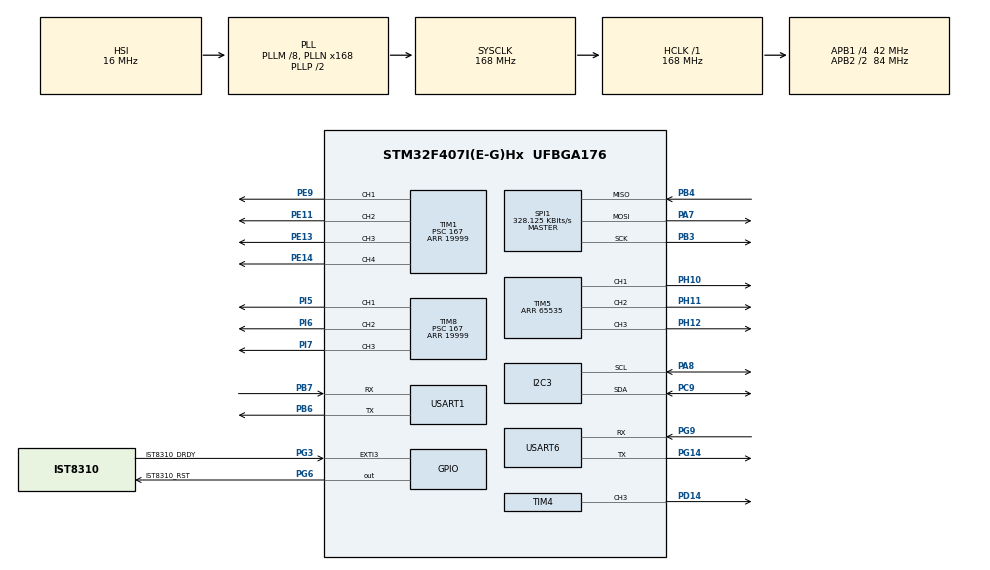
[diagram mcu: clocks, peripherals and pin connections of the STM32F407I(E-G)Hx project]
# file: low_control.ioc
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Dma.Request0=SPI1_RX
Dma.Request1=SPI1_TX
Dma.SPI1_RX.0.Direction=DMA_PERIPH_TO_MEMORY
Dma.SPI1_RX.0.FIFOMode=DMA_FIFOMODE_DISABLE
Dma.SPI1_RX.0.Instance=DMA2_Stream0
Dma.SPI1_RX.0.MemDataAlignment=DMA_MDATAALIGN_BYTE
Dma.SPI1_RX.0.MemInc=DMA_MINC_ENABLE
Dma.SPI1_RX.0.Mode=DMA_NORMAL
Dma.SPI1_RX.0.PeriphDataAlignment=DMA_PDATAALIGN_BYTE
Dma.SPI1_RX.0.PeriphInc=DMA_PINC_DISABLE
Dma.SPI1_RX.0.Priority=DMA_PRIORITY_VERY_HIGH
Dma.SPI1_TX.1.Direction=DMA_MEMORY_TO_PERIPH
Dma.SPI1_TX.1.FIFOMode=DMA_FIFOMODE_DISABLE
Dma.SPI1_TX.1.Instance=DMA2_Stream3
Dma.SPI1_TX.1.MemDataAlignment=DMA_MDATAALIGN_BYTE
Dma.SPI1_TX.1.MemInc=DMA_MINC_ENABLE
Dma.SPI1_TX.1.Mode=DMA_NORMAL
Dma.SPI1_TX.1.PeriphDataAlignment=DMA_PDATAALIGN_BYTE
Dma.SPI1_TX.1.PeriphInc=DMA_PINC_DISABLE
Dma.SPI1_TX.1.Priority=DMA_PRIORITY_HIGH
I2C3.I2C_Mode=I2C_Fast
Mcu.Family=STM32F4
Mcu.Name=STM32F407I(E-G)Hx
Mcu.Package=UFBGA176
NVIC.DMA2_Stream0_IRQn=true\:0\:0\:false\:false\:true\:false\:true\:true
NVIC.DMA2_Stream3_IRQn=true\:0\:0\:false\:false\:true\:false\:true\:true
NVIC.PriorityGroup=NVIC_PRIORITYGROUP_4
NVIC.USART1_IRQn=true\:0\:0\:false\:false\:true\:true\:true\:true
NVIC.USART6_IRQn=true\:0\:0\:false\:false\:true\:true\:true\:true
PA13.Mode=Serial_Wire
PA13.Signal=SYS_JTMS-SWDIO
PA14.Mode=Serial_Wire
PA14.Signal=SYS_JTCK-SWCLK
PA8.Mode=I2C
PA8.Signal=I2C3_SCL
PB3.Mode=Full_Duplex_Master
PB3.Signal=SPI1_SCK
PB4.Mode=Full_Duplex_Master
PB4.Signal=SPI1_MISO
PA7.Mode=Full_Duplex_Master
PA7.Signal=SPI1_MOSI
PB6.Mode=Asynchronous
PB6.Signal=USART1_TX
PB7.Mode=Asynchronous
PB7.Signal=USART1_RX
PD14.Signal=S_TIM4_CH3
PC9.Mode=I2C
PC9.Signal=I2C3_SDA
PE11.Signal=S_TIM1_CH2
PE13.Signal=S_TIM1_CH3
PE14.Signal=S_TIM1_CH4
PE9.Signal=S_TIM1_CH1
PG14.Mode=Asynchronous
PG14.Signal=USART6_TX
PG3.GPIO_Label=IST8310_DRDY
PG3.GPIO_PuPd=GPIO_PULLUP
PG3.Signal=GPXTI3
PG6.GPIO_Label=IST8310_RST
PG6.GPIO_PuPd=GPIO_PULLUP
PG6.GPIO_Speed=GPIO_SPEED_FREQ_MEDIUM
PG6.PinState=GPIO_PIN_SET
PG6.Signal=GPIO_Output
PG9.Mode=Asynchronous
PG9.Signal=USART6_RX
PH0-OSC_IN.Mode=HSE-External-Oscillator
PH0-OSC_IN.Signal=RCC_OSC_IN
PH1-OSC_OUT.Mode=HSE-External-Oscillator
PH1-OSC_OUT.Signal=RCC_OSC_OUT
PH10.Signal=S_TIM5_CH1
PH11.Signal=S_TIM5_CH2
PH12.Signal=S_TIM5_CH3
PI5.Signal=S_TIM8_CH1
PI6.Signal=S_TIM8_CH2
PI7.Signal=S_TIM8_CH3
ProjectManager.HeapSize=0x200
ProjectManager.StackSize=0x400
ProjectManager.TargetToolchain=CMake
RCC.48MHZClocksFreq_Value=84000000
RCC.AHBFreq_Value=168000000
RCC.APB1CLKDivider=RCC_HCLK_DIV4
RCC.APB1Freq_Value=42000000
RCC.APB1TimFreq_Value=84000000
RCC.APB2CLKDivider=RCC_HCLK_DIV2
RCC.APB2Freq_Value=84000000
RCC.APB2TimFreq_Value=168000000
RCC.CortexFreq_Value=168000000
RCC.HCLKFreq_Value=168000000
RCC.HSE_VALUE=12000000
RCC.HSI_VALUE=16000000
RCC.LSE_VALUE=32768
RCC.PLLM=8
RCC.PLLN=168
RCC.SYSCLKFreq_VALUE=168000000
RCC.SYSCLKSource=RCC_SYSCLKSOURCE_PLLCLK
RCC.VCOOutputFreq_Value=336000000
SH.S_TIM1_CH1.0=TIM1_CH1,PWM Generation1 CH1
SH.S_TIM1_CH2.0=TIM1_CH2,PWM Generation2 CH2
SH.S_TIM1_CH3.0=TIM1_CH3,PWM Generation3 CH3
SH.S_TIM1_CH4.0=TIM1_CH4,PWM Generation4 CH4
SH.S_TIM4_CH3.0=TIM4_CH3,PWM Generation3 CH3
SH.S_TIM5_CH1.0=TIM5_CH1,PWM Generation1 CH1
SH.S_TIM5_CH2.0=TIM5_CH2,PWM Generation2 CH2
SH.S_TIM5_CH3.0=TIM5_CH3,PWM Generation3 CH3
SH.S_TIM8_CH1.0=TIM8_CH1,PWM Generation1 CH1
SH.S_TIM8_CH2.0=TIM8_CH2,PWM Generation2 CH2
SH.S_TIM8_CH3.0=TIM8_CH3,PWM Generation3 CH3
SPI1.BaudRatePrescaler=SPI_BAUDRATEPRESCALER_256
SPI1.CLKPhase=SPI_PHASE_2EDGE
SPI1.CLKPolarity=SPI_POLARITY_HIGH
SPI1.CalculateBaudRate=328.125 KBits/s
SPI1.Direction=SPI_DIRECTION_2LINES
SPI1.Mode=SPI_MODE_MASTER
SPI1.VirtualType=VM_MASTER
TIM1.Channel-PWM\ Generation1\ CH1=TIM_CHANNEL_1
TIM1.Channel-PWM\ Generation2\ CH2=TIM_CHANNEL_2
TIM1.Channel-PWM\ Generation3\ CH3=TIM_CHANNEL_3
TIM1.Channel-PWM\ Generation4\ CH4=TIM_CHANNEL_4
TIM1.Period=19999
TIM1.Prescaler=167
TIM1.Pulse-PWM\ Generation1\ CH1=2000
TIM1.Pulse-PWM\ Generation2\ CH2=2000
TIM1.Pulse-PWM\ Generation3\ CH3=2000
TIM4.Channel-PWM\ Generation3\ CH3=TIM_CHANNEL_3
TIM5.Channel-PWM\ Generation1\ CH1=TIM_CHANNEL_1
TIM5.Channel-PWM\ Generation2\ CH2=TIM_CHANNEL_2
TIM5.Channel-PWM\ Generation3\ CH3=TIM_CHANNEL_3
TIM5.Period=65535
TIM5.Pulse-PWM\ Generation1\ CH1=10000
TIM5.Pulse-PWM\ Generation2\ CH2=10000
TIM8.Channel-PWM\ Generation1\ CH1=TIM_CHANNEL_1
TIM8.Channel-PWM\ Generation2\ CH2=TIM_CHANNEL_2
TIM8.Channel-PWM\ Generation3\ CH3=TIM_CHANNEL_3
TIM8.Period=19999
TIM8.Prescaler=167
TIM8.Pulse-PWM\ Generation1\ CH1=2000
TIM8.Pulse-PWM\ Generation2\ CH2=2000
USART1.VirtualMode=VM_ASYNC
USART6.VirtualMode=VM_ASYNC
VP_TIM1_VS_ClockSourceINT.Mode=Internal
VP_TIM4_VS_ClockSourceINT.Mode=Internal
VP_TIM5_VS_ClockSourceINT.Mode=Internal
VP_TIM8_VS_ClockSourceINT.Mode=Internal
board=custom

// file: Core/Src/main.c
/* USER CODE BEGIN Header */
/**
  ******************************************************************************
  * @file           : main.c
  * @brief          : Main program body
  ******************************************************************************
  * @attention
  *
  * Copyright (c) 2026 STMicroelectronics.
  * All rights reserved.
  *
  * This software is licensed under terms that can be found in the LICENSE file
  * in the root directory of this software component.
  * If no LICENSE file comes with this software, it is provided AS-IS.
  *
  ******************************************************************************
  */
/* USER CODE END Header */
#include "main.h"
#include "dma.h"
#include "i2c.h"
#include "spi.h"
#include "tim.h"
#include "usart.h"
#include "gpio.h"

/* USER CODE BEGIN Includes */
#include "usermain.h"
#include "Safety.h"
/* USER CODE END Includes */

void SystemClock_Config(void);

int main(void)
{

  /* MCU Configuration--------------------------------------------------------*/

  /* Reset of all peripherals, Initializes the Flash interface and the Systick. */
  HAL_Init();

  /* Configure the system clock */
  SystemClock_Config();

  /* Initialize all configured peripherals */
  MX_GPIO_Init();
  MX_DMA_Init();
  MX_I2C3_Init();
  MX_SPI1_Init();
  MX_TIM1_Init();
  MX_TIM8_Init();
  MX_USART1_UART_Init();
  MX_USART6_UART_Init();
  MX_TIM4_Init();
  MX_TIM5_Init();

  /* Infinite loop */
  while (1)
  {

  }
}

void SystemClock_Config(void)
{
  RCC_OscInitTypeDef RCC_OscInitStruct = {0};
  RCC_ClkInitTypeDef RCC_ClkInitStruct = {0};

  /** Configure the main internal regulator output voltage
  */
  __HAL_RCC_PWR_CLK_ENABLE();
  __HAL_PWR_VOLTAGESCALING_CONFIG(PWR_REGULATOR_VOLTAGE_SCALE1);

  /** Initializes the RCC Oscillators according to the specified parameters
  * in the RCC_OscInitTypeDef structure.
  */
  RCC_OscInitStruct.OscillatorType = RCC_OSCILLATORTYPE_HSI;
  RCC_OscInitStruct.HSIState = RCC_HSI_ON;
  RCC_OscInitStruct.HSICalibrationValue = RCC_HSICALIBRATION_DEFAULT;
  RCC_OscInitStruct.PLL.PLLState = RCC_PLL_ON;
  RCC_OscInitStruct.PLL.PLLSource = RCC_PLLSOURCE_HSI;
  RCC_OscInitStruct.PLL.PLLM = 8;
  RCC_OscInitStruct.PLL.PLLN = 168;
  RCC_OscInitStruct.PLL.PLLP = RCC_PLLP_DIV2;
  RCC_OscInitStruct.PLL.PLLQ = 4;
  if (HAL_RCC_OscConfig(&RCC_OscInitStruct) != HAL_OK)
  {
    Error_Handler();
  }

  /** Initializes the CPU, AHB and APB buses clocks
  */
  RCC_ClkInitStruct.ClockType = RCC_CLOCKTYPE_HCLK|RCC_CLOCKTYPE_SYSCLK
                              |RCC_CLOCKTYPE_PCLK1|RCC_CLOCKTYPE_PCLK2;
  RCC_ClkInitStruct.SYSCLKSource = RCC_SYSCLKSOURCE_PLLCLK;
  RCC_ClkInitStruct.AHBCLKDivider = RCC_SYSCLK_DIV1;
  RCC_ClkInitStruct.APB1CLKDivider = RCC_HCLK_DIV4;
  RCC_ClkInitStruct.APB2CLKDivider = RCC_HCLK_DIV2;

  if (HAL_RCC_ClockConfig(&RCC_ClkInitStruct, FLASH_LATENCY_5) != HAL_OK)
  {
    Error_Handler();
  }
}

void Error_Handler(void)
{
  /* USER CODE BEGIN Error_Handler_Debug */
  /* User can add his own implementation to report the HAL error return state */
  Safety_FaultISR(SAFETY_FATAL);
  __disable_irq();
  while (1)
  {
  }
  /* USER CODE END Error_Handler_Debug */
}
